# LKS32MC03x register map
Vendor: Linko Ltd.; Series: LKS32MC03x; File version: 1.0
CPU: CM0 r1p0, little endian, MPU, no FPU, 3 interrupt priority bits
Registers are 32-bit, read-write, reset 0x0 unless marked. A register's access mark holds for its fields unless they carry their own. Offsets are from the block's base; [hi:lo] are bit positions; {n}, {i} and the like mark numbered series.

## SYS — SYS registers
Base 0x40000000
0x00 AFE_ADC ro — Raw data from AD Core
0x04 AFE_INFO ro — Chip Version
0x0C OPA_SEL — OPA mux enable
  [0] OPA_SEL_EN — OPA mux selection enable
    0=DISABLED (Sample ADC_CH8 when ADC_CH8 is selected); 1=ENABLED (Sample OPA1_OUT instead of ADC_CH8)
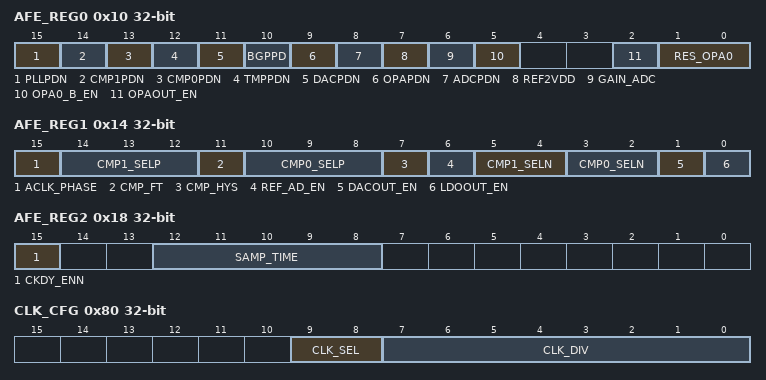
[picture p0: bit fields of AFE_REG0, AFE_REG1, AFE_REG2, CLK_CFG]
0x10 AFE_REG0 — Analog reg0
  [15] PLLPDN — PLL on-off
    0=OFF (OFF(Default)); 1=ON
  [14] CMP1PDN — Comparator 1 on-off
    0=OFF (OFF(Default)); 1=ON
  [13] CMP0PDN — Comparator 0 on-off
    0=OFF (OFF(Default)); 1=ON
  [12] TMPPDN — Temp sensor on-off
    0=OFF (OFF(Default)); 1=ON
  [11] DACPDN — DAC on-off
    0=OFF (OFF(Default)); 1=ON
  [10] BGPPD — Bandgap on-off
    0=ON (ON(Default)); 1=OFF
  [9] OPAPDN — OPA on-off
    0=OFF (OFF(Default)); 1=ON
  [8] ADCPDN — ADC on-off
    0=OFF (OFF(Default)); 1=ON
  [7] REF2VDD — ADC reference select
    0=2P4 (Use internal 2.4V as ADC reference); 1=AVDD (Use AVDD as ADC reference)
  [6] GAIN_ADC — ADC gain select
    0=0P66 (0.66 times); 1=1 times
  [5] OPA0_B_EN — OPA0 input B enable
    0=OPA0 (Use OPA0_IP/OPA0_IN); 1=OPA0_B (Use OPA0_IP_B/OPA0_IN_B)
  [2] OPAOUT_EN — OPA output enable
    0=DISABLED (No output); 1=ENABLED (OPA output to P0[7])
  [1:0] RES_OPA0 — OPA0 feedback resistor
    0=200k_10k; 1=190k_20k; 2=180k_30k; 3=170k_40k
0x14 AFE_REG1 — Analog reg1
  [15] ACLK_PHASE — ADC Clock edge select
    0=P (Posedge); 1=N (Negedge)
  [14:12] CMP1_SELP — Comparator 1 positive input select
    0=CMP1_IP0; 1=OPA0_IP; 2=OPA0_OUT; 3=CMP1_IP1; 4=CMP1_IP2; 5=CMP1_IP3
  [11] CMP_FT — Comparator fast mode
    0=NORMAL (200ns); 1=FAST (less than 30ns)
  [10:8] CMP0_SELP — Comparator 0 positive input select
    0=CMP0_IP0; 1=OPA0_IP; 2=OPA0_OUT; 3=CMP0_IP1; 4=CMP0_IP2; 5=CMP0_IP3
  [7] CMP_HYS — Comparator hystersis select
    0=20mV; 1=0mV
  [6] REF_AD_EN — ADC REF output enable
    0=DISABLED (ADC REF output disabled); 1=ENABLED (ADC REF output to P0[0])
  [5:4] CMP1_SELN — Comparator 1 negative input select
    0=CMP1_IN; 1=REF; 2=DACOUT; 3=BEMFx_MID
  [3:2] CMP0_SELN — Comparator 0 negative input select
    0=CMP0_IN; 1=REF; 2=DACOUT; 3=BEMFx_MID
  [1] DACOUT_EN — DAC output enable
    0=DISABLED (DAC output disabled); 1=ENABLED (DAC output to P0[0])
  [0] LDOOUT_EN — LDO output enable
    0=DISABLED (LDO output disabled); 1=ENABLED (LDO output to P0[0])
0x18 AFE_REG2 — Analog reg2
  [15] CKDY_ENN — Delay ADC Clock
    0=ENABLED (Enable ADC clock delay); 1=DISABLED (Disable ADC clock delay)
  [12:8] SAMP_TIME — ADC sample time
    {v}={v+4}ACLK ({v+4} ADC clocks) (v=0..31)
0x1C AFE_REG3 — Analog reg3
  [6:4] REFTRIM — Bandgap output voltage tune
    0=0mV; 1=6P6mV (6.6mV); 2=13P2mV (13.2mV); 3=19P8mV (19.8mV); 4=N26P4mV (-26.4mV); 5=N19P8mV (-19.8mV); 6=N13P2mV (-13.2mV); 7=N6P6mV (-6.6mV)
0x20 AFE_REG4 — Analog reg4
  [2:0] LDO15TRIM — LDO15 tune
    0=0P12 (0.12); 1=0P08 (0.08); 2=0P04 (0.04); 3=0; 4=N0P04 (-0.04); 5=N0P08 (-0.08); 6=0P121 (0.12); 7=0P122 (0.12)
0x24 AFE_REG5 — Analog reg5
  [3:0] RCLTRIM — 32kHz RC clock tune
    0=0; 1=0P12 (0.12); 2=0P27 (0.27); 3=0P46 (0.46); 4=N0P13 (-0.13); 8=N0P23 (-0.23); 12=N0P32 (-0.32)
0x28 AFE_REG6 — Analog reg6
  [5:0] RCHTRIM — 4MHz RC clock tune
    0=0P0000; 1=0P0125 (0.0125); 2=0P0250 (0.025); 3=0P0375 (0.0375); 4=0P0500 (0.05); 5=0P0625 (0.0625); 6=0P0750 (0.075); 7=0P0875 (0.0875); 8=0P1000 (0.1); 9=0P1125 (0.1125); 10=0P1250 (0.125); 11=0P1375 (0.1375); 12=0P1500 (0.15); 13=0P1625 (0.1625); 14=0P1750 (0.175); 15=0P1875 (0.1875); 16=0P2000 (0.2); 17=0P2125 (0.2125); 18=0P2250 (0.225); 19=0P2375 (0.2375); 20=0P2500 (0.25); 21=0P2625 (0.2625); 22=0P2750 (0.275); 23=0P2875 (0.2875); 24=0P3000 (0.3); 25=0P3125 (0.3125); 26=0P3250 (0.325); 27=0P3375 (0.3375); 28=0P3500 (0.35); 29=0P3625 (0.3625); 30=0P3750 (0.375); 31=0P3875 (0.3875); 32=N0P4000 (-0.4); 33=N0P3875 (-0.3875); 34=N0P3750 (-0.375); 35=N0P3625 (-0.3625); 36=N0P3500 (-0.35); 37=N0P3375 (-0.3375); 38=N0P3250 (-0.325); 39=N0P3125 (-0.3125); 40=N0P3000 (-0.3); 41=N0P2875 (-0.2875); 42=N0P2750 (-0.275); 43=N0P2625 (-0.2625); 44=N0P2500 (-0.25); 45=N0P2375 (-0.2375); 46=N0P2250 (-0.225); 47=N0P2125 (-0.2125); 48=N0P2000 (-0.2); 49=N0P1875 (-0.1875); 50=N0P1750 (-0.175); 51=N0P1625 (-0.1625); 52=N0P1500 (-0.15); 53=N0P1375 (-0.1375); 54=N0P1250 (-0.125); 55=N0P1125 (-0.1125); 56=N0P1000 (-0.1); 57=N0P875 (-0.0875); 58=N0P750 (-0.075); 59=N0P625 (-0.0625); 60=N0P500 (-0.05); 61=N0P375 (-0.0375); 62=N0P250 (-0.025); 63=N0P125 (-0.0125)
0x2C AFE_DAC — DAC digital input
  [7:0] DAC_IN — DAC digital input value
0x80 CLK_CFG — Clock configuration
  [9:8] CLK_SEL — Select PLL or HRC as system clock
    0=HRC (Use 4MHz HRC as system clock); 1=PLL (Use PLL clock as system clock); 2=LRC (Use LRC clock as system clock); 3=LRC2 (Use LRC clock as system clock)
  [7:0] CLK_DIV — Clock enable of every 8 cycles
    0=DIV8 (Divided by 8); 17=DIV4 (Divided by 4); 85=DIV2 (Divided by 2); 255=DIV1 (Divided by 1)
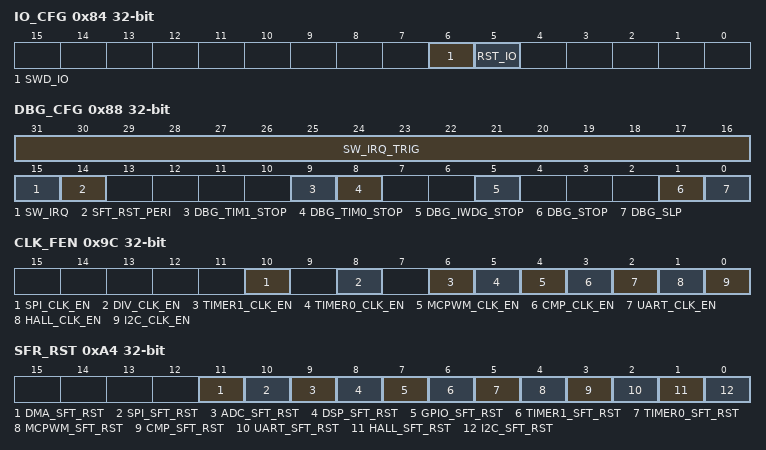
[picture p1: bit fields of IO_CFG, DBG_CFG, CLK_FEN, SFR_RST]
0x84 IO_CFG — IO configuration
  [6] SWD_IO — Use SWD as GPIO
    0=ENABLED (P1[9:8] As GPIO); 1=DISABLED (P1[9:8] As SWD)
  [5] RST_IO — Use RSTn as GPIO
    0=DISABLED (As RSTn); 1=ENABLED (As GPIO)
0x88 DBG_CFG — IO configuration
  [31:16] SW_IRQ_TRIG wo — Write to generate sw IRQ
  [15] SW_IRQ rw-once — Software IRQ flag
  [14] SFT_RST_PERI — Whether debug soft reset could reset peripherals' registers
    0=DISABLED (Not reset); 1=ENABLED (Reset)
  [9] DBG_TIM1_STOP — Stop Timer1 during debug
    0=DISABLED (Not stop); 1=ENABLED (Stop)
  [8] DBG_TIM0_STOP — Stop Timer0 during debug
    0=DISABLED (Not stop); 1=ENABLED (Stop)
  [5] DBG_IWDG_STOP — Stop IWDG during debug
    0=DISABLED (Not stop); 1=ENABLED (Stop)
  [1] DBG_STOP — Debug stop mode
    0=DISABLED (Not debug); 1=ENABLED (Debug)
  [0] DBG_SLP — Debug sleep mode
    0=DISABLED (Not debug); 1=ENABLED (Debug)
0x90 CLK_DIV0 — I2C Clock division ratio
  [15:0] I2C_CLK_DIV — I2C_CLK=MCLK/(CLK_DIV0+1)
0x98 CLK_DIV2 — UART 0/1 Clock division ratio
  [15:0] UART_CLK_DIV — UART_CLK=MCLK/(CLK_DIV2+1)
0x9C CLK_FEN — Peripheral clock enable
  [all] fields
    0=DISABLED (Clock is disabled); 1=ENABLED (Clock is enabled)
  [10] SPI_CLK_EN — SPI module clock enable
  [8] DIV_CLK_EN — DIV module clock enable
  [6] TIMER1_CLK_EN — Timer1 module clock enable
  [5] TIMER0_CLK_EN — Timer0 module clock enable
  [4] MCPWM_CLK_EN — MCPWM module clock enable
  [3] CMP_CLK_EN — CMP module clock enable
  [2] UART_CLK_EN — UART module clock enable
  [1] HALL_CLK_EN — Hall module clock enable
  [0] I2C_CLK_EN — I2C module clock enable
0xA4 SFR_RST — Peripheral soft reset
  [all] fields
    0=RELEASE (reset release); 1=RESET
  [11] DMA_SFT_RST — DMA module soft reset
  [10] SPI_SFT_RST — SPI module soft reset
  [9] ADC_SFT_RST — ADC interface module soft reset
  [8] DSP_SFT_RST — DSP module soft reset
  [7] GPIO_SFT_RST — GPIO module soft reset
  [6] TIMER1_SFT_RST — Timer1 module soft reset
  [5] TIMER0_SFT_RST — Timer0 module soft reset
  [4] MCPWM_SFT_RST — MCPWM module soft reset
  [3] CMP_SFT_RST — CMP module soft reset
  [2] UART_SFT_RST — UART module soft reset
  [1] HALL_SFT_RST — Hall module soft reset
  [0] I2C_SFT_RST — I2C module soft reset
0xA8 PROTECT wo — System reg protect
  [15:0] PSW — Write 0x7A83 to unlock protection
    0x7A83=PSW (system register write protect password)
0xD0 FLSE wo — Flash erase protection
  [15:0] PSW — Write 0x8FCA to unlock protection
    0x8FCA=PSW (flash erase protect password)
0xD4 FLSP wo — Flash program protection
  [15:0] PSW — Write 0x8F35 to unlock protection
    0x8F35=PSW (flash program protect password)
